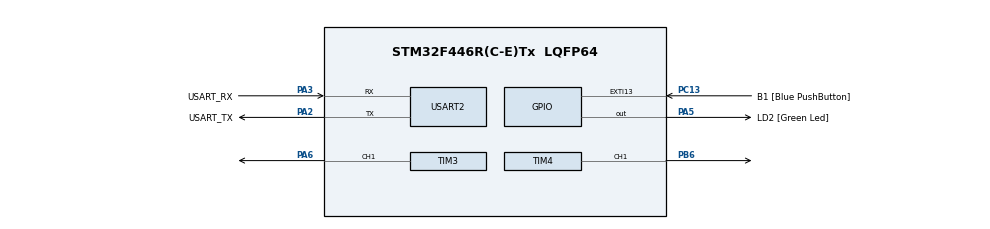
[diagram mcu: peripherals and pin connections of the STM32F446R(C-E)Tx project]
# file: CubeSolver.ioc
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Dma.Request0=USART2_TX
Dma.USART2_TX.0.Direction=DMA_MEMORY_TO_PERIPH
Dma.USART2_TX.0.FIFOMode=DMA_FIFOMODE_DISABLE
Dma.USART2_TX.0.Instance=DMA1_Stream6
Dma.USART2_TX.0.MemDataAlignment=DMA_MDATAALIGN_BYTE
Dma.USART2_TX.0.MemInc=DMA_MINC_ENABLE
Dma.USART2_TX.0.Mode=DMA_NORMAL
Dma.USART2_TX.0.PeriphDataAlignment=DMA_PDATAALIGN_BYTE
Dma.USART2_TX.0.PeriphInc=DMA_PINC_DISABLE
Dma.USART2_TX.0.Priority=DMA_PRIORITY_LOW
Mcu.Family=STM32F4
Mcu.Name=STM32F446R(C-E)Tx
Mcu.Package=LQFP64
NVIC.DMA1_Stream6_IRQn=true\:0\:0\:false\:false\:true\:false\:true\:true
NVIC.PriorityGroup=NVIC_PRIORITYGROUP_0
NVIC.TIM3_IRQn=true\:0\:0\:false\:false\:true\:true\:true\:true
NVIC.TIM4_IRQn=true\:0\:0\:false\:false\:true\:true\:true\:true
NVIC.TIM6_DAC_IRQn=true\:0\:0\:false\:false\:true\:false\:true\:true
NVIC.TimeBase=TIM6_DAC_IRQn
NVIC.TimeBaseIP=TIM6
NVIC.USART2_IRQn=true\:0\:0\:false\:false\:true\:true\:true\:true
PA13.GPIO_Label=TMS
PA13.Signal=SYS_JTMS-SWDIO
PA14.GPIO_Label=TCK
PA14.Signal=SYS_JTCK-SWCLK
PA2.GPIO_Label=USART_TX
PA2.Mode=Asynchronous
PA2.Signal=USART2_TX
PA3.GPIO_Label=USART_RX
PA3.Mode=Asynchronous
PA3.Signal=USART2_RX
PA5.GPIO_Label=LD2 [Green Led]
PA5.Signal=GPIO_Output
PA6.Signal=S_TIM3_CH1
PB3.GPIO_Label=SWO
PB3.Signal=SYS_JTDO-SWO
PB6.Signal=S_TIM4_CH1
PC13.GPIO_Label=B1 [Blue PushButton]
PC13.GPIO_ModeDefaultEXTI=GPIO_MODE_IT_FALLING
PC13.Signal=GPXTI13
PC14-OSC32_IN.Signal=RCC_OSC32_IN
PC15-OSC32_OUT.Signal=RCC_OSC32_OUT
PH0-OSC_IN.Signal=RCC_OSC_IN
PH1-OSC_OUT.Signal=RCC_OSC_OUT
ProjectManager.HeapSize=0x200
ProjectManager.StackSize=0x400
ProjectManager.TargetToolchain=CMake
RCC.AHBFreq_Value=16000000
RCC.APB1CLKDivider=RCC_HCLK_DIV2
RCC.APB1Freq_Value=8000000
RCC.APB1TimFreq_Value=16000000
RCC.APB2Freq_Value=16000000
RCC.APB2TimFreq_Value=16000000
RCC.CortexFreq_Value=16000000
RCC.FLatency-AdvancedSettings=FLASH_LATENCY_0
RCC.HCLKFreq_Value=16000000
RCC.HSE_VALUE=8000000
RCC.HSI_VALUE=16000000
RCC.LSE_VALUE=32768
RCC.PLLN=336
RCC.PLLP=RCC_PLLP_DIV4
RCC.SYSCLKFreq_VALUE=16000000
RCC.USBFreq_Value=168000000
RCC.VCOOutputFreq_Value=336000000
SH.S_TIM3_CH1.0=TIM3_CH1,PWM Generation1 CH1
SH.S_TIM4_CH1.0=TIM4_CH1,PWM Generation1 CH1
TIM3.Channel-PWM\ Generation1\ CH1=TIM_CHANNEL_1
TIM4.Channel-PWM\ Generation1\ CH1=TIM_CHANNEL_1
USART2.VirtualMode=VM_ASYNC
VP_SYS_VS_tim6.Mode=TIM6
VP_TIM3_VS_ClockSourceINT.Mode=Internal
VP_TIM4_VS_ClockSourceINT.Mode=Internal
board=NUCLEO-F446RE

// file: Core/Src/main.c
/* USER CODE BEGIN Header */
/**
  ******************************************************************************
  * @file           : main.c
  * @brief          : Main program body
  ******************************************************************************
  * @attention
  *
  * Copyright (c) 2026 STMicroelectronics.
  * All rights reserved.
  *
  * This software is licensed under terms that can be found in the LICENSE file
  * in the root directory of this software component.
  * If no LICENSE file comes with this software, it is provided AS-IS.
  *
  ******************************************************************************
  */
/* USER CODE END Header */
#include "main.h"
#include "dma.h"
#include "tim.h"
#include "usart.h"
#include "gpio.h"

/* USER CODE BEGIN Includes */
#include "Application.h"
#include "Instructions.h"
/* USER CODE END Includes */

void SystemClock_Config(void);

int main(void)
{
  /* Reset of all peripherals, Initializes the Flash interface and the Systick. */
  HAL_Init();

  /* Configure the system clock */
  SystemClock_Config();

  /* Initialize all configured peripherals */
  MX_GPIO_Init();
  MX_DMA_Init();
  MX_TIM3_Init();
  MX_TIM4_Init();
  MX_USART2_UART_Init();

  // Testing UART transmission
  const char *message = "Hello, world!\n\r";
  USART2_transmit(message);

  Application app = Application_init();

  extern bool action_pending;
  extern RingBuffer rx_buffer;

  while (true)
  {
    if (action_pending)
    {
      Instruction_interpret(&rx_buffer, app.hal.motors);
    }
  }
}

void SystemClock_Config(void)
{
  LL_FLASH_SetLatency(LL_FLASH_LATENCY_0);
  while(LL_FLASH_GetLatency()!= LL_FLASH_LATENCY_0)
  {
  }
  LL_PWR_SetRegulVoltageScaling(LL_PWR_REGU_VOLTAGE_SCALE3);
  LL_PWR_DisableOverDriveMode();
  LL_RCC_HSI_SetCalibTrimming(16);
  LL_RCC_HSI_Enable();

   /* Wait till HSI is ready */
  while(LL_RCC_HSI_IsReady() != 1)
  {

  }
  LL_RCC_SetAHBPrescaler(LL_RCC_SYSCLK_DIV_1);
  LL_RCC_SetAPB1Prescaler(LL_RCC_APB1_DIV_2);
  LL_RCC_SetAPB2Prescaler(LL_RCC_APB2_DIV_1);
  LL_RCC_SetSysClkSource(LL_RCC_SYS_CLKSOURCE_HSI);

   /* Wait till System clock is ready */
  while(LL_RCC_GetSysClkSource() != LL_RCC_SYS_CLKSOURCE_STATUS_HSI)
  {

  }
  LL_SetSystemCoreClock(16000000);

   /* Update the time base */
  if (HAL_InitTick (TICK_INT_PRIORITY) != HAL_OK)
  {
    Error_Handler();
  }
  LL_RCC_SetTIMPrescaler(LL_RCC_TIM_PRESCALER_TWICE);
}

void HAL_TIM_PeriodElapsedCallback(TIM_HandleTypeDef *htim)
{
  if (htim->Instance == TIM6)
  {
    HAL_IncTick();
  }
}

void Error_Handler(void)
{
  __disable_irq();
  while (1)
  {
  }
}
